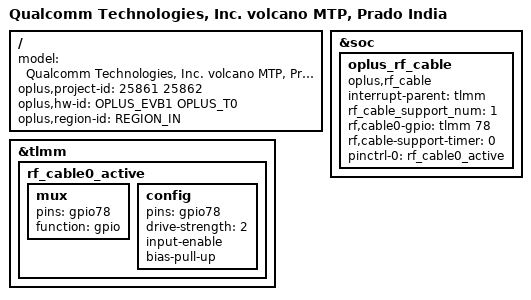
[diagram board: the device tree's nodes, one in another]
/dts-v1/;
/plugin/;
#include <dt-bindings/oplus/hw-id.h>
#include <dt-bindings/input/linux-event-codes.h>
#include "../qcom/volcano-mtp-overlay.dts"
#include "volcano_overlay_common.dtsi"
#include "prado_overlay_common.dtsi"
#include "oplus_fp/oplus_fp_25811_25861_25862.dtsi"

/* India use graphite battery in PCB T0 and not support UFCS charging. */
#include "oplus_chg/oplus-chg-prado-india-T0.dtsi"
#include "tp/prado-oplus-tp-25811.dtsi"
#include "oplus_misc/oplus-misc-25861-IN-T0.dtsi"
#include "sensor/prado-sensor-25811-25861.dtsi"
#include "nfc/prado-nfc-pn560.dtsi"
#include "region-id.h.dtsi"

/ {
    model = "Qualcomm Technologies, Inc. volcano MTP, Prado India";

    oplus,project-id = <25861 25862>;
    oplus,hw-id = <OPLUS_EVB1 OPLUS_T0>; /* use graphite battery in T0 board */
    oplus,region-id = <REGION_IN>; /* India region */
};

&tlmm {
  //#ifdef OPLUS_FEATURE_RF_CABLE_DETECT
  //modify for rf_cable
  rf_cable0_active: rf_cable0_active {
    mux {
      pins = "gpio78";
      function = "gpio";
    };
    config {
      pins = "gpio78";
      drive-strength = <2>;
      input-enable;
      bias-pull-up;
    };
  };
  //#endif /* OPLUS_FEATURE_RF_CABLE_DETECT */
};

&soc {
  //#ifdef OPLUS_FEATURE_RF_CABLE_DETECT
  //modify for rf_cable
  oplus_rf_cable {
    compatible = "oplus,rf_cable";
    interrupt-parent = <&tlmm>;
    rf_cable_support_num = <1>;
    rf,cable0-gpio = <&tlmm 78 0>;
    rf,cable-support-timer = <0>;
    pinctrl-names = "rf_cable_active";
    pinctrl-0 = <&rf_cable0_active>;
  };
  //#endif /* OPLUS_FEATURE_RF_CABLE_DETECT */
};
